# cslr_cpu_001 register map
Vendor: Texas Instruments
Peripheral module from a debugger description file (folder C5505).
Address unit: 16 bits
Registers are 16-bit, access not given, reset 0x0 unless marked. A register's access mark holds for its fields unless they carry their own. Offsets are as the file gives them; lines under a group give offsets from that group; [hi:lo] are bit positions; {n}, {i} and the like mark numbered series; 'fields as' and 'values as' point back to an identical list; <NAME> marks a mode.

## CPU — The C55x CPU is main processing unit of the DSP.
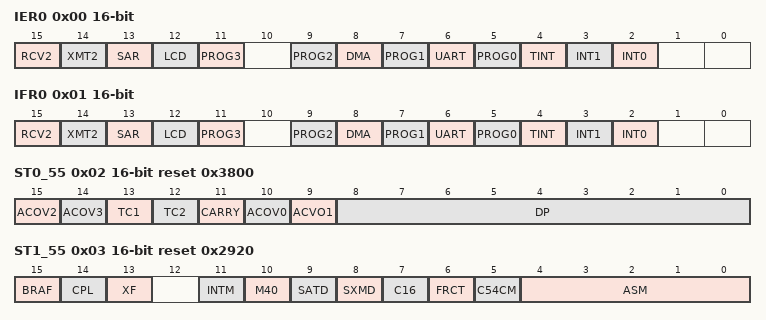
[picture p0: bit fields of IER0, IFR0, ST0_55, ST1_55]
0x00 IER0 — Interrupt Enable Register 0
  [all] fields
    0=DISABLE (Disable interrupt.); 1=ENABLE (Enable interrupt.)
  [15] RCV2 rw — I2S2 receive interrupt mask bit.
  [14] XMT2 rw — I2S2 transmit interrupt mask bit
  [13] SAR rw — 10-bit SAR A/D conversion or pen interrupt mask bit.
  [12] LCD rw — LCD interrupt mask bit.
  [11] PROG3 rw — Programmable receive interrupt 3 mask bit. This bit is used as either the I2S1 receive interrupt mask bit or the MMC/SD1 SDIO interrupt mask bit. The function of this bit is selected depending on the setting of the SP1MODE bit in the external bus selection register. If SP1MODE = 00b, this bit supports MMC/SD1 SDIO interrupts. If SP1MODE = 01, this bit supports I2S1 interrupts.
  [9] PROG2 rw — Programmable transmit interrupt 2 mask bit. This bit is used as either the I2S1 transmit interrupt mask bit or the MMC/SD1 interrupt mask bit. The function of this bit is selected depending on the setting of the SP1MODE bit in the external bus selection register. If SP1MODE = 00b, this bit supports MMC/SD1 interrupts. If SP1MODE = 01, this bit supports I2S1 interrupts.
  [8] DMA rw — DMA aggregated interrupt mask bit.
  [7] PROG1 rw — Programmable receive interrupt 1 mask bit. This bit is used as either the I2S0 receive interrupt mask bit or the MMC/SD0 SDIO interrupt mask bit. The function of this bit is selected depending on the setting of the SP0MODE bit in the external bus selection register. If SP0MODE = 00b, this bit supports MMC/SD0 SDIO interrupts. If SP0MODE = 01, this bit supports I2S0 interrupts.
  [6] UART rw — UART interrupt mask bit.
  [5] PROG0 rw — Programmable transmit interrupt 0 mask bit. This bit is used either the I2S0 transmit interrupt mask bit or the MMC/SD0 interrupt mask bit. The function of this bit is selected depending on the setting of the SP0MODE bit in the external bus selection register. If SP0MODE = 00b, this bit supports MMC/SD0 interrupts. If SP0MODE = 01, this bit supports I2S0 interrupts.
  [4] TINT rw — Timer aggregated interrupt mask bit.
  [3] INT1 rw — External user interrupt #1 mask bit.
  [2] INT0 rw — External user interrupt #0 mask bit.
0x01 IFR0 — Interrupt Flag Register 0
  [all] fields
    0=DISABLED (Interrupt is disabled.); 1=ENABLED (Interrupt is enabled.)
  [15] RCV2 rw — I2S2 receive interrupt flag bit.
  [14] XMT2 rw — I2S2 transmit interrupt flag bit
  [13] SAR rw — 10-bit SAR A/D conversion or pen interrupt flag bit.
  [12] LCD rw — LCD interrupt flag bit.
  [11] PROG3 rw — Programmable receive interrupt 3 flag bit. This bit is used as either the I2S1 receive interrupt flag bit or the MMC/SD1 SDIO interrupt flag bit. The function of this bit is selected depending on the setting of the SP1MODE bit in the external bus selection register. If SP1MODE = 00b, this bit supports MMC/SD1 SDIO interrupts. If SP1MODE = 01, this bit supports I2S1 interrupts.
  [9] PROG2 rw — Programmable transmit interrupt 2 flag bit. This bit is used as either the I2S1 transmit interrupt flag bit or the MMC/SD1 interrupt flag bit. The function of this bit is selected depending on the setting of the SP1MODE bit in the external bus selection register. If SP1MODE = 00b, this bit supports MMC/SD1 interrupts. If SP1MODE = 01, this bit supports I2S1 interrupts.
  [8] DMA rw — DMA aggregated interrupt flag bit.
  [7] PROG1 rw — Programmable receive interrupt 1 flag bit. This bit is used as either the I2S0 receive interrupt flag bit or the MMC/SD0 SDIO interrupt flag bit. The function of this bit is selected depending on the setting of the SP0MODE bit in the external bus selection register. If SP0MODE = 00b, this bit supports MMC/SD0 SDIO interrupts. If SP0MODE = 01, this bit supports I2S0 interrupts.
  [6] UART rw — UART interrupt flag bit.
  [5] PROG0 rw — Programmable transmit interrupt 0 flag bit. This bit is used either the I2S0 transmit interrupt flag bit or the MMC/SD0 interrupt flag bit. The function of this bit is selected depending on the setting of the SP0MODE bit in the external bus selection register. If SP0MODE = 00b, this bit supports MMC/SD0 interrupts. If SP0MODE = 01, this bit supports I2S0 interrupts.
  [4] TINT rw — Timer aggregated interrupt flag bit.
  [3] INT1 rw — External user interrupt #1 flag bit.
  [2] INT0 rw — External user interrupt #0 flag bit.
0x02 ST0_55 rw reset 0x3800 — Status Register 0
  [15] ACOV2 — AC2 overflow flag.
    0=OFF (Overflow not detected.); 1=ON (Overflow detected.)
  [14] ACOV3 — AC3 overflow flag.
    0=OFF (Overflow not detected.); 1=ON (Overflow detected.)
  [13] TC1 — Test/control flag 1.
    0=OFF (Test/control bit is cleared.); 1=ON (Test/control bit is set.)
  [12] TC2 — Test/control flag 2.
    values as TC1
  [11] CARRY — Carry bit.
    0=OFF (Carry bit is not set.); 1=ON (Carry bit is set.)
  [10] ACOV0 — AC0 overflow flag.
    0=OFF (Overflow not detected.); 1=ON (Overflow detected.)
  [9] ACVO1 — AC1 overflow flag.
    0=OFF (Overflow not detected.); 1=ON (Overflow detected.)
  [8:0] DP — Copy of the 9 most significant bits of the data page register (DP).
0x03 ST1_55 reset 0x2920 — Status Register 1
  [15] BRAF rw — Block-repeat active flag.
    0=OFF (No block-repeat operation is active.); 1=ON (A block-repeat operation is active.)
  [14] CPL rw — Compiler mode bit.
    0=OFF (DP direct addressing mode. Direct accesses to data space are made relative to the data page register (DP).); 1=ON (SP direct addressing mode. Direct accesses to data space are made relative to the data stack pointer (SP). The DSP is said to be in compiler mode.)
  [13] XF rw — External flag.
    0=OFF (XF is set low.); 1=ON (XF is set high.)
  [11] INTM rw — Interrupt mode bit.
    0=OFF (All unmasked interrupts are enabled.); 1=ON (All maskable interrupts are disabled.)
  [10] M40 rw — Computation mode bit for the D unit.
    0=OFF (32-bit mode.); 1=ON (40-bit mode.)
  [9] SATD rw — Saturation mode bit for the D unit.
    0=OFF (Off. No saturation is performed.); 1=ON (On. If an operation performed by the D unit results in an overflow, the result is saturated.)
  [8] SXMD rw — Sign-extension mode bit for the D unit.
    0=OFF (Sign-extension mode is off.); 1=ON (Sign-extension mode is on.)
  [7] C16 rw — Dual 16-bit arithmetic mode bit. If C54CM = 1: The arithmetic performed in the D-unit ALU depends on C16. If C54CM = 0: The CPU ignores C16. The instruction syntax alone determines whether dual 16-bit arithmetic or 32-bit arithmetic is used.
    0=OFF (Off. For an instruction that is affected by C16, the D-unit ALU performs one 32-bit operation.); 1=ON (On. For an instruction that is affected by C16, the D-unit ALU performs two 16-bit operations in parallel.)
  [6] FRCT rw — Fractional mode bit.
    0=OFF (Off. Results of multiply operations are not shifted.); 1=ON (On. Results of multiply operations are shifted left by 1 bit for decimal point adjustment. This is required when you multiply two signed Q15 values and you need a Q31 result.)
  [5] C54CM rw — TMS320C54x DSPcompatible mode bit.
    0=OFF (Disabled. The CPU supports code written for a TMS320C55x (C55x) DSP.); 1=ON (Enabled. This mode must be set when you are using code that was originally developed for a TMS320C54x (C54x) DSP. All the C55x DSP CPU resources remain available; therefore, as you translate code, you can take advantage of the additional features on the C55x DSP to optimize your code.)
  [4:0] ASM rw — Accumulator shift mode bits.
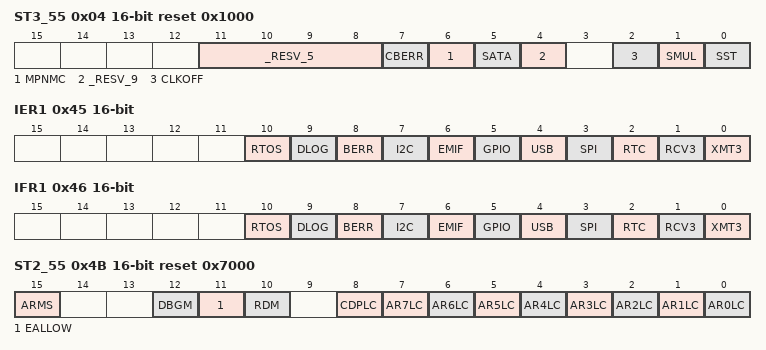
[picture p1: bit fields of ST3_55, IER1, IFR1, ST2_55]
0x04 ST3_55 reset 0x1000 (reset mask 0xF0FF) — Status Register 3
  [11:8] _RESV_5 — (access N)
  [7] CBERR rw — CPU bus error flag.
    0=OFF (The flag has been cleared by your program or by a reset.); 1=ON (An internal bus error has been detected.)
  [6] MPNMC rw — Microprocessor/microcomputer mode bit.
    0=OFF (Microcomputer mode. The on-chip ROM is enabled; it is addressable in program space.); 1=ON (Microprocessor mode. The on-chip ROM is disabled; it is not in the program-space map.)
  [5] SATA rw — Saturation mode bit for the A unit.
    0=OFF (Saturation mode on A unit is off. No saturatio is performed.); 1=ON (Saturation mode on A unit is on. If a calculation in the A-unit ALU results in an overflow, the result is saturated to 7FFFh (for overflow in the positive direction) or 8000h (for overflow in the negative direction).)
  [4] _RESV_9 — Always write 0 to this bit. (access N)
  [2] CLKOFF rw — CLKOUT disable bit.
    0=ENABLE (CLKOUT pin is enabled.); 1=DISABLE (CLKOUT pin is disabled.)
  [1] SMUL rw — Saturation-on-multiplication mode bit.
    0=OFF (Saturation-on-multiplication mode is off.); 1=ON (Saturation-on-multiplication mode is on. When SMUL = 1, FRCT = 1, and SATD = 1, the result of 18000h × 18000h is saturated to 7FFF FFFFh (regardless of the value of the M40 bit). This forces the product of the two negative numbers to be a positive number.)
  [0] SST rw — Saturate-on-store mode bit.
    0=OFF (Saturation-on-store mode is off.); 1=ON (Saturation-on-store mode is on. For an instruction that is affected by SST, the CPU saturates a shifted or unshifted accumulator value before storing it.)
0x45 IER1 — Interrupt Enable Register 1
  [all] fields
    0=DISABLE (Disable interrupt.); 1=ENABLE (Enable interrupt.)
  [10] RTOS rw — Real-time operating system interrupt mask bit.
  [9] DLOG rw — Data log interrupt mask bit.
  [8] BERR rw — Bus error interrupt mask bit.
  [7] I2C rw — I2C interrupt mask bit.
  [6] EMIF rw — EMIF error interrupt mask bit.
  [5] GPIO rw — GPIO aggregated interrupt mask bit.
  [4] USB rw — USB interrupt mask bit.
  [3] SPI rw — SPI interrupt mask bit.
  [2] RTC rw — Wakeup or real-time clock interrupt mask bit.
  [1] RCV3 rw — I2S3 receive interrupt mask bit.
  [0] XMT3 rw — I2S3 transmit interrupt mask bit.
0x46 IFR1 — Interrupt Flag Register 1
  [all] fields
    values as the fields of IFR0
  [10] RTOS rw — Real-time operating system interrupt flag bit.
  [9] DLOG rw — Data log interrupt flag bit.
  [8] BERR rw — Bus error interrupt flag bit.
  [7] I2C rw — I2C interrupt flag bit.
  [6] EMIF rw — EMIF error interrupt flag bit.
  [5] GPIO rw — GPIO aggregated interrupt flag bit.
  [4] USB rw — USB interrupt flag bit.
  [3] SPI rw — SPI interrupt flag bit.
  [2] RTC rw — Wakeup or real-time clock interrupt flag bit.
  [1] RCV3 rw — I2S3 receive interrupt flag bit.
  [0] XMT3 rw — I2S3 transmit interrupt flag bit.
0x49 IVPD rw reset 0xFFFF — Interrupt vector pointer register. IVPD points to the 256-byte program page for interrupt vectors 0-15.
  [15:0] IVPD — IVPD value.
0x4A IVPH rw reset 0xFFFF — Interrupt vector pointer register. IVPH points to the 256-byte program page for interrupt vectors 16-23.
  [15:0] IVPH — IVPH value.
0x4B ST2_55 reset 0x7000 — Status Register 2
  [15] ARMS rw — AR mode switch bit.
    0=OFF (DSP mode operands, which provide efficient execution of DSP intensive applications. Among these operands are those that use reverse carry propagation when adding to or subtracting from a pointer. Short-offset operands are not available.); 1=ON (Control mode operands, which enable optimized code size for control system applications. The short-offset operand *ARn(short(#k3)) is available. (Other offsets require a 2-byte extension on an instruction, and instructions with these extensions cannot be executed in parallel with other instructions.))
  [12] DBGM rw — Debug mode bit.
    0=OFF (Debug events are enabled.); 1=ON (Debug events are disabled. The emulator cannot access memory or registers. Software breakpoints still cause the CPU to halt, but hardware breakpoints or halt requests are ignored.)
  [11] EALLOW rw — Emulation access enable bit.
    0=OFF (Write access to non-CPU emulation registers is disabled.); 1=ON (Write access to non-CPU emulation registers is enabled.)
  [10] RDM rw — Rounding mode bit.
    0=OFF (Round to the infinite. The CPU adds 8000h (2 raised to the 15th power) to the 40-bit operand. Then the CPU clears bits 15 through 0 to generate a rounded result in a 24- or 16-bit representation. For a 24-bit representation, only bits 39 through 16 of the result are meaningful. For a 16-bit representation, only bits 31 through 16 of the result are meaningful.); 1=ON (Round to the nearest. The rounding depends on bits 15 through 0 of the 40-bit operand, as shown by the following if statements. The rounded result is in a 24-bit representation (in bits 39 through 16) or a 16-bit representation (in bits 31 through 16).)
  [8] CDPLC rw — CDP linear/circular configuration bit.
    0=OFF (CDP is used for linear addessing.); 1=ON (CDP is used for circular addressing.)
  [n] AR{n}LC rw (n=0..7) — AR{n} linear/circular configuration bit.
    0=OFF (AR{n} is used for linear addressing.); 1=ON (AR{n} is used for circular addressing.)
